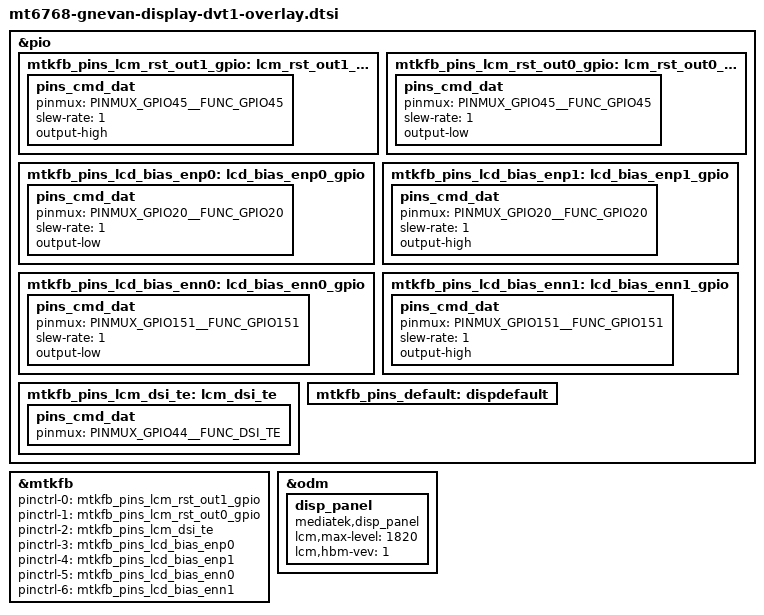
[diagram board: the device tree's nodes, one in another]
/*
 * Copyright (c) 2022 MediaTek Inc.
 *
 * This program is free software; you can redistribute it and/or modify
 * it under the terms of the GNU General Public License version 2 as
 * published by the Free Software Foundation.
 *
 * This program is distributed in the hope that it will be useful,
 * but WITHOUT ANY WARRANTY; without even the implied warranty of
 * MERCHANTABILITY or FITNESS FOR A PARTICULAR PURPOSE.  See the
 * GNU General Public License for more details.
 */

/* DISPSYS GPIO standardization */
&pio {
	mtkfb_pins_lcm_rst_out1_gpio: lcm_rst_out1_gpio {
		pins_cmd_dat {
			pinmux = <PINMUX_GPIO45__FUNC_GPIO45>;
			slew-rate = <1>;
			output-high;
		};
	};

	mtkfb_pins_lcm_rst_out0_gpio: lcm_rst_out0_gpio {
		pins_cmd_dat {
			pinmux = <PINMUX_GPIO45__FUNC_GPIO45>;
			slew-rate = <1>;
			output-low;
		};
	};

	mtkfb_pins_lcd_bias_enp0: lcd_bias_enp0_gpio {
		pins_cmd_dat {
			pinmux = <PINMUX_GPIO20__FUNC_GPIO20>;
			slew-rate = <1>;
			output-low;
		};
	};

	mtkfb_pins_lcd_bias_enp1: lcd_bias_enp1_gpio {
		pins_cmd_dat {
			pinmux = <PINMUX_GPIO20__FUNC_GPIO20>;
			slew-rate = <1>;
			output-high;
		};
	};

	mtkfb_pins_lcd_bias_enn0: lcd_bias_enn0_gpio {
		pins_cmd_dat {
			pinmux = <PINMUX_GPIO151__FUNC_GPIO151>;
			slew-rate = <1>;
			output-low;
		};
	};

	mtkfb_pins_lcd_bias_enn1: lcd_bias_enn1_gpio {
		pins_cmd_dat {
			pinmux = <PINMUX_GPIO151__FUNC_GPIO151>;
			slew-rate = <1>;
			output-high;
		};
	};

	mtkfb_pins_lcm_dsi_te: lcm_dsi_te {
		pins_cmd_dat {
			pinmux = <PINMUX_GPIO44__FUNC_DSI_TE>;
		};
	};

	mtkfb_pins_default: dispdefault {
	};
};

&mtkfb {
	pinctrl-names =
		"lcm_rst_out1_gpio", "lcm_rst_out0_gpio",
		"mode_te_te",
		"lcd_bias_enp0_gpio", "lcd_bias_enp1_gpio",
		"lcd_bias_enn0_gpio", "lcd_bias_enn1_gpio";
	pinctrl-0 = <&mtkfb_pins_lcm_rst_out1_gpio>;
	pinctrl-1 = <&mtkfb_pins_lcm_rst_out0_gpio>;
	pinctrl-2 = <&mtkfb_pins_lcm_dsi_te>;
	pinctrl-3 = <&mtkfb_pins_lcd_bias_enp0>;
	pinctrl-4 = <&mtkfb_pins_lcd_bias_enp1>;
	pinctrl-5 = <&mtkfb_pins_lcd_bias_enn0>;
	pinctrl-6 = <&mtkfb_pins_lcd_bias_enn1>;
	status = "okay";
};

/* DISPSYS GPIO standardization end*/

&odm {
	disp_panel: disp_panel {
		compatible = "mediatek,disp_panel";
		lcm,max-level = <1820>;
		lcm,hbm-vev = <1>;
	};
};

